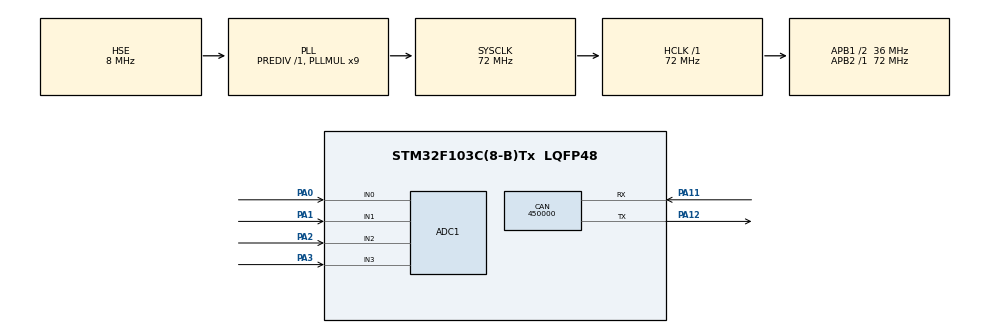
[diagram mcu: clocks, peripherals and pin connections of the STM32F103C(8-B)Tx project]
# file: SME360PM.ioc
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ADC1.Channel-0\#ChannelRegularConversion=ADC_CHANNEL_0
ADC1.Channel-1\#ChannelRegularConversion=ADC_CHANNEL_0
ADC1.Channel-2\#ChannelRegularConversion=ADC_CHANNEL_0
ADC1.Channel-3\#ChannelRegularConversion=ADC_CHANNEL_0
ADC1.ContinuousConvMode=DISABLE
ADC1.NbrOfConversion=4
ADC1.NbrOfConversionFlag=1
ADC1.Rank-0\#ChannelRegularConversion=1
ADC1.Rank-1\#ChannelRegularConversion=2
ADC1.Rank-2\#ChannelRegularConversion=3
ADC1.Rank-3\#ChannelRegularConversion=4
ADC1.SamplingTime-0\#ChannelRegularConversion=ADC_SAMPLETIME_1CYCLE_5
ADC1.SamplingTime-1\#ChannelRegularConversion=ADC_SAMPLETIME_1CYCLE_5
ADC1.SamplingTime-2\#ChannelRegularConversion=ADC_SAMPLETIME_1CYCLE_5
ADC1.SamplingTime-3\#ChannelRegularConversion=ADC_SAMPLETIME_1CYCLE_5
ADC1.master=1
CAN.BS1=CAN_BS1_3TQ
CAN.CalculateBaudRate=450000
CAN.CalculateTimeBit=2222
CAN.CalculateTimeQuantum=444.44444444444446
Dma.ADC1.0.Direction=DMA_PERIPH_TO_MEMORY
Dma.ADC1.0.Instance=DMA1_Channel1
Dma.ADC1.0.MemDataAlignment=DMA_MDATAALIGN_HALFWORD
Dma.ADC1.0.MemInc=DMA_MINC_ENABLE
Dma.ADC1.0.Mode=DMA_NORMAL
Dma.ADC1.0.PeriphDataAlignment=DMA_PDATAALIGN_HALFWORD
Dma.ADC1.0.PeriphInc=DMA_PINC_DISABLE
Dma.ADC1.0.Priority=DMA_PRIORITY_LOW
Dma.Request0=ADC1
Mcu.Family=STM32F1
Mcu.Name=STM32F103C(8-B)Tx
Mcu.Package=LQFP48
NVIC.CAN1_RX1_IRQn=true\:0\:0\:false\:false\:true\:true\:true\:true
NVIC.DMA1_Channel1_IRQn=true\:0\:0\:false\:false\:true\:false\:true\:true
NVIC.PriorityGroup=NVIC_PRIORITYGROUP_4
PA0-WKUP.Signal=ADCx_IN0
PA1.Signal=ADCx_IN1
PA11.Mode=CAN_Activate
PA11.Signal=CAN_RX
PA12.Mode=CAN_Activate
PA12.Signal=CAN_TX
PA13.Mode=Serial_Wire
PA13.Signal=SYS_JTMS-SWDIO
PA14.Mode=Serial_Wire
PA14.Signal=SYS_JTCK-SWCLK
PA2.Signal=ADCx_IN2
PA3.Signal=ADCx_IN3
PD0-OSC_IN.Mode=HSE-External-Oscillator
PD0-OSC_IN.Signal=RCC_OSC_IN
PD1-OSC_OUT.Mode=HSE-External-Oscillator
PD1-OSC_OUT.Signal=RCC_OSC_OUT
ProjectManager.HeapSize=0x200
ProjectManager.StackSize=0x400
ProjectManager.TargetToolchain=STM32CubeIDE
RCC.ADCPresc=RCC_ADCPCLK2_DIV6
RCC.AHBFreq_Value=72000000
RCC.APB1CLKDivider=RCC_HCLK_DIV2
RCC.APB1Freq_Value=36000000
RCC.APB1TimFreq_Value=72000000
RCC.APB2Freq_Value=72000000
RCC.APB2TimFreq_Value=72000000
RCC.HCLKFreq_Value=72000000
RCC.PLLMUL=RCC_PLL_MUL9
RCC.PLLSourceVirtual=RCC_PLLSOURCE_HSE
RCC.SYSCLKFreq_VALUE=72000000
RCC.SYSCLKSource=RCC_SYSCLKSOURCE_PLLCLK
RCC.USBFreq_Value=72000000
SH.ADCx_IN0.0=ADC1_IN0,IN0
SH.ADCx_IN1.0=ADC1_IN1,IN1
SH.ADCx_IN2.0=ADC1_IN2,IN2
SH.ADCx_IN3.0=ADC1_IN3,IN3
board=custom

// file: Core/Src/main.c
/* USER CODE BEGIN Header */
/**
  ******************************************************************************
  * @file           : main.c
  * @brief          : Main program body
  *
  * To request data device ID should be
  * 0x42 (dec 66)
  * DLC = 1
  * data[0] = 1
  * setup_array = [0x01, 0x00, 0x00, 0x00, 0x42, 0x1, 0x00, 0x00, 0x00, 0x00, 0x00, 0x00, 0x00]
  ******************************************************************************
  * @attention
  *
  * <h2><center>&copy; Copyright (c) 2021 STMicroelectronics.
  * All rights reserved.</center></h2>
  *
  * This software component is licensed by ST under BSD 3-Clause license,
  * the "License"; You may not use this file except in compliance with the
  * License. You may obtain a copy of the License at:
  *                        opensource.org/licenses/BSD-3-Clause
  *
  ******************************************************************************
  */
/* USER CODE END Header */
#include "main.h"

CAN_HandleTypeDef hcan;
ADC_HandleTypeDef hadc1;
DMA_HandleTypeDef hdma_adc1;

void SystemClock_Config(void);
static void MX_GPIO_Init(void);
static void MX_CAN_Init(void);
static void MX_DMA_Init(void);
static void MX_ADC1_Init(void);

/* USER CODE BEGIN 0 */

// ~~~~~~~~~~~~~~~~~~  CAN VARIABLES  ~~~~~~~~~~~~~~~~~~
CAN_TxHeaderTypeDef TxHeader;
CAN_RxHeaderTypeDef RxHeader;

uint8_t TxData[8];
uint8_t RxData[8];

uint32_t TxMailbox;

int datacheck = 0;

// ~~~~~~~~~~~~~~~~~~  ADC VARIABLES  ~~~~~~~~~~~~~~~~~~
volatile uint16_t adcResultsDMA[4];
const int adcChannelCount = sizeof(adcResultsDMA) / sizeof(adcResultsDMA[0]);
volatile int adcConversionComplete = 0;

// ~~~~~~~~~~~~~~~~~~  CAN INTERRUPT  ~~~~~~~~~~~~~~~~~~
void HAL_CAN_RxFifo1MsgPendingCallback(CAN_HandleTypeDef *hcan)
{
	HAL_CAN_GetRxMessage(hcan, CAN_RX_FIFO1, &RxHeader, RxData);
	if (RxHeader.DLC == 1 && RxData[0] == 1) // Check if only 1 byte of data && if it is requesting data
	{
		datacheck = 1;
	}
}

// ~~~~~~~~~~~~~~~~~~  ADC INTERRUPT  ~~~~~~~~~~~~~~~~~~
void HAL_ADC_ConvCpltCallback(ADC_HandleTypeDef *hadc)
{
	adcConversionComplete = 1;
}

// ~~~~~~~~~~~~~~~~~~  TRANSFORM INT TO BYTE  ~~~~~~~~~~~~~~~~~~
void intTobyte(void)
{
	for (int i =0; i < 4; i++)
	{
		TxData[2*i] = (adcResultsDMA[i] >> 8) & 0xff; // big byte
		TxData[2*i+1] = adcResultsDMA[i] & 0xff;      // little byte
	}

}

/* USER CODE END 0 */

int main(void)
{
  /* MCU Configuration--------------------------------------------------------*/

  /* Reset of all peripherals, Initializes the Flash interface and the Systick. */
  HAL_Init();

  /* Configure the system clock */
  SystemClock_Config();

  /* Initialize all configured peripherals */
  MX_GPIO_Init();
  MX_CAN_Init();
  MX_DMA_Init();
  MX_ADC1_Init();
  /* USER CODE BEGIN 2 */

  HAL_CAN_Start(&hcan);

  // Activate the notification
  HAL_CAN_ActivateNotification(&hcan, CAN_IT_RX_FIFO1_MSG_PENDING);

  TxHeader.DLC = 8;  // data length
  TxHeader.IDE = CAN_ID_STD;
  TxHeader.RTR = CAN_RTR_DATA;
  TxHeader.StdId = 0x67;  // ID 103

    // ADC Calibration
    while(HAL_ADCEx_Calibration_Start(&hadc1) != HAL_OK);

  /* USER CODE END 2 */

  /* Infinite loop */
  while (1)
  {

    /* USER CODE BEGIN 3 */

	  HAL_ADC_Start_DMA(&hadc1, (uint32_t*)&adcResultsDMA, adcChannelCount);
	  while (adcConversionComplete == 0)
	  {

	  }
	  intTobyte();
	  adcConversionComplete = 0;

	  if (datacheck)
	  {
		  HAL_CAN_AddTxMessage(&hcan, &TxHeader, TxData, &TxMailbox);
		  HAL_GPIO_TogglePin(GPIOC, GPIO_PIN_13);
		  datacheck = 0;
	  }
  }
  /* USER CODE END 3 */
}

void SystemClock_Config(void)
{
  RCC_OscInitTypeDef RCC_OscInitStruct = {0};
  RCC_ClkInitTypeDef RCC_ClkInitStruct = {0};
  RCC_PeriphCLKInitTypeDef PeriphClkInit = {0};

  /** Initializes the RCC Oscillators according to the specified parameters
  * in the RCC_OscInitTypeDef structure.
  */
  RCC_OscInitStruct.OscillatorType = RCC_OSCILLATORTYPE_HSE;
  RCC_OscInitStruct.HSEState = RCC_HSE_ON;
  RCC_OscInitStruct.HSEPredivValue = RCC_HSE_PREDIV_DIV1;
  RCC_OscInitStruct.HSIState = RCC_HSI_ON;
  RCC_OscInitStruct.PLL.PLLState = RCC_PLL_ON;
  RCC_OscInitStruct.PLL.PLLSource = RCC_PLLSOURCE_HSE;
  RCC_OscInitStruct.PLL.PLLMUL = RCC_PLL_MUL9;
  if (HAL_RCC_OscConfig(&RCC_OscInitStruct) != HAL_OK)
  {
    Error_Handler();
  }
  /** Initializes the CPU, AHB and APB buses clocks
  */
  RCC_ClkInitStruct.ClockType = RCC_CLOCKTYPE_HCLK|RCC_CLOCKTYPE_SYSCLK
                              |RCC_CLOCKTYPE_PCLK1|RCC_CLOCKTYPE_PCLK2;
  RCC_ClkInitStruct.SYSCLKSource = RCC_SYSCLKSOURCE_PLLCLK;
  RCC_ClkInitStruct.AHBCLKDivider = RCC_SYSCLK_DIV1;
  RCC_ClkInitStruct.APB1CLKDivider = RCC_HCLK_DIV2;
  RCC_ClkInitStruct.APB2CLKDivider = RCC_HCLK_DIV1;

  if (HAL_RCC_ClockConfig(&RCC_ClkInitStruct, FLASH_LATENCY_2) != HAL_OK)
  {
    Error_Handler();
  }

  PeriphClkInit.PeriphClockSelection = RCC_PERIPHCLK_ADC;
  PeriphClkInit.AdcClockSelection = RCC_ADCPCLK2_DIV6;
  if (HAL_RCCEx_PeriphCLKConfig(&PeriphClkInit) != HAL_OK)
  {
    Error_Handler();
  }
}

static void MX_CAN_Init(void)
{

  hcan.Instance = CAN1;
  hcan.Init.Prescaler = 18;
  hcan.Init.Mode = CAN_MODE_NORMAL;
  hcan.Init.SyncJumpWidth = CAN_SJW_1TQ;
  hcan.Init.TimeSeg1 = CAN_BS1_2TQ;
  hcan.Init.TimeSeg2 = CAN_BS2_1TQ;
  hcan.Init.TimeTriggeredMode = DISABLE;
  hcan.Init.AutoBusOff = DISABLE;
  hcan.Init.AutoWakeUp = DISABLE;
  hcan.Init.AutoRetransmission = DISABLE;
  hcan.Init.ReceiveFifoLocked = DISABLE;
  hcan.Init.TransmitFifoPriority = DISABLE;
  if (HAL_CAN_Init(&hcan) != HAL_OK)
  {
    Error_Handler();
  }
  /* USER CODE BEGIN CAN_Init 2 */

  CAN_FilterTypeDef canfilterconfig;

  canfilterconfig.FilterBank = 0;  // which filter bank to use from the assigned ones
  canfilterconfig.FilterFIFOAssignment = CAN_FILTER_FIFO1;
  canfilterconfig.FilterIdHigh = 0x42<<5;
  canfilterconfig.FilterIdLow = 0x0000;
  canfilterconfig.FilterMaskIdHigh = 0x42<<5;
  canfilterconfig.FilterMaskIdLow = 0x0000;
  canfilterconfig.FilterMode = CAN_FILTERMODE_IDMASK;
  canfilterconfig.FilterScale = CAN_FILTERSCALE_32BIT;
  canfilterconfig.FilterActivation = ENABLE;
  canfilterconfig.SlaveStartFilterBank = 0;  // doesn't matter in single can controllers

  HAL_CAN_ConfigFilter(&hcan, &canfilterconfig);

  /* USER CODE END CAN_Init 2 */

}

static void MX_GPIO_Init(void)
{
  GPIO_InitTypeDef GPIO_InitStruct = {0};

  /* GPIO Ports Clock Enable */
  __HAL_RCC_GPIOC_CLK_ENABLE();
  __HAL_RCC_GPIOD_CLK_ENABLE();
  __HAL_RCC_GPIOA_CLK_ENABLE();

  /*Configure GPIO pin Output Level */
  HAL_GPIO_WritePin(GPIOC, GPIO_PIN_13, GPIO_PIN_RESET);

  /*Configure GPIO pin : PC13 */
  GPIO_InitStruct.Pin = GPIO_PIN_13;
  GPIO_InitStruct.Mode = GPIO_MODE_OUTPUT_PP;
  GPIO_InitStruct.Pull = GPIO_NOPULL;
  GPIO_InitStruct.Speed = GPIO_SPEED_FREQ_LOW;
  HAL_GPIO_Init(GPIOC, &GPIO_InitStruct);
  HAL_GPIO_WritePin(GPIOC, GPIO_PIN_13, 1); //Led off

}

static void MX_DMA_Init(void)
{

  /* DMA controller clock enable */
  __HAL_RCC_DMA1_CLK_ENABLE();

  /* DMA interrupt init */
  /* DMA1_Channel1_IRQn interrupt configuration */
  HAL_NVIC_SetPriority(DMA1_Channel1_IRQn, 0, 0);
  HAL_NVIC_EnableIRQ(DMA1_Channel1_IRQn);

}

static void MX_ADC1_Init(void)
{

  ADC_ChannelConfTypeDef sConfig = {0};

  /** Common config
  */
  hadc1.Instance = ADC1;
  hadc1.Init.ScanConvMode = ADC_SCAN_ENABLE;
  hadc1.Init.ContinuousConvMode = DISABLE;
  hadc1.Init.DiscontinuousConvMode = DISABLE;
  hadc1.Init.ExternalTrigConv = ADC_SOFTWARE_START;
  hadc1.Init.DataAlign = ADC_DATAALIGN_RIGHT;
  hadc1.Init.NbrOfConversion = 4;
  if (HAL_ADC_Init(&hadc1) != HAL_OK)
  {
    Error_Handler();
  }

  /** Configure Regular Channel
  */
  sConfig.Channel = ADC_CHANNEL_0;
  sConfig.Rank = ADC_REGULAR_RANK_1;
  sConfig.SamplingTime = ADC_SAMPLETIME_28CYCLES_5;
  if (HAL_ADC_ConfigChannel(&hadc1, &sConfig) != HAL_OK)
  {
    Error_Handler();
  }

  /** Configure Regular Channel
  */
  sConfig.Channel = ADC_CHANNEL_1;
  sConfig.Rank = ADC_REGULAR_RANK_2;
  sConfig.SamplingTime = ADC_SAMPLETIME_28CYCLES_5;
  if (HAL_ADC_ConfigChannel(&hadc1, &sConfig) != HAL_OK)
  {
    Error_Handler();
  }

  /** Configure Regular Channel
  */
  sConfig.Channel = ADC_CHANNEL_2;
  sConfig.Rank = ADC_REGULAR_RANK_3;
  sConfig.SamplingTime = ADC_SAMPLETIME_28CYCLES_5;
  if (HAL_ADC_ConfigChannel(&hadc1, &sConfig) != HAL_OK)
  {
    Error_Handler();
  }

  /** Configure Regular Channel
  */
  sConfig.Channel = ADC_CHANNEL_3;
  sConfig.Rank = ADC_REGULAR_RANK_4;
  sConfig.SamplingTime = ADC_SAMPLETIME_28CYCLES_5;
  if (HAL_ADC_ConfigChannel(&hadc1, &sConfig) != HAL_OK)
  {
    Error_Handler();
  }

}

void Error_Handler(void)
{
  __disable_irq();
  while (1)
  {
  }
}

/************************ (C) COPYRIGHT STMicroelectronics *****END OF FILE****/
